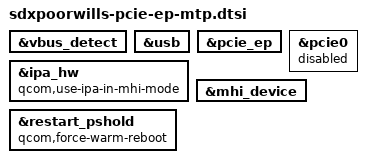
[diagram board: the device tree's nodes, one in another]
/* Copyright (c) 2018-2019, The Linux Foundation. All rights reserved.
 *
 * This program is free software; you can redistribute it and/or modify
 * it under the terms of the GNU General Public License version 2 and
 * only version 2 as published by the Free Software Foundation.
 *
 * This program is distributed in the hope that it will be useful,
 * but WITHOUT ANY WARRANTY; without even the implied warranty of
 * MERCHANTABILITY or FITNESS FOR A PARTICULAR PURPOSE.  See the
 * GNU General Public License for more details.
 */

#include "sdxpoorwills-mtp.dtsi"

&vbus_detect {
	status = "okay";
};

&usb {
	/delete-property/ iommus;
};

&pcie_ep {
	status = "okay";
};

&ipa_hw {
	qcom,use-ipa-in-mhi-mode;
};

&pcie0 {
	status = "disabled";
};

&mhi_device {
	status = "okay";
};

&restart_pshold {
	qcom,force-warm-reboot;
};
